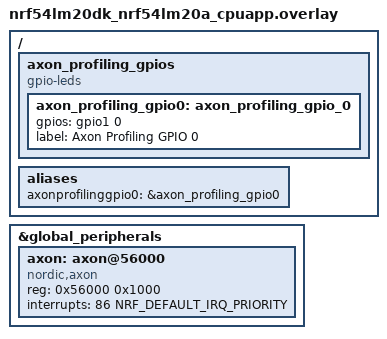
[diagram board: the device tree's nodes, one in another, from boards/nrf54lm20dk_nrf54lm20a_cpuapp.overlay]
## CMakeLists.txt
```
#
# Copyright (c) 2024, Nordic Semiconductor ASA. All Rights Reserved.
#
# The information contained herein is confidential property of Nordic Semiconductor ASA.
# The use, copying, transfer or disclosure of such information is prohibited except by
# express written agreement with Nordic Semiconductor ASA.
#
cmake_minimum_required(VERSION 3.20.0)

set(CMAKE_COMPILE_WARNING_AS_ERROR ON)

find_package(Zephyr REQUIRED HINTS $ENV{ZEPHYR_BASE})

project(axon_fe_mfcc VERSION 0.1.0 LANGUAGES C)

target_sources(app PRIVATE
	src/axon_app_mfcc_zephyr.c
	src/axon_app_mfcc.c
)

# 
# mfcc name is specified through kConfig. However for automated builds the
# environment variable AXON_MFCC_NAME can override kConfig.
#
if (DEFINED ENV{NRF_AXON_MFCC_NAME})
    message(STATUS "NRF_AXON_MFCC_NAME DEFINED $ENV{NRF_AXON_MFCC_NAME}, OVERRIDES CONFIG_NRF_AXON_MFCC_NAME ${CONFIG_NRF_AXON_MFCC_NAME}")
    zephyr_compile_definitions(
        NRF_AXON_MFCC_NAME=$ENV{NRF_AXON_MFCC_NAME}
    )
else()
    message(STATUS "NRF_AXON_MFCC_NAME NOT DEFINED, USING CONFIG_NRF_AXON_MFCC_NAME ${CONFIG_NRF_AXON_MFCC_NAME}")
    zephyr_compile_definitions(
        NRF_AXON_MFCC_NAME=${CONFIG_NRF_AXON_MFCC_NAME}
    )
endif()
```

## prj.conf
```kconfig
CONFIG_PRINTK=y
CONFIG_LOG=y
CONFIG_LOG_MODE_IMMEDIATE=y

CONFIG_NRF_AXON=y

CONFIG_NRF_AXON_MFCC=y
CONFIG_NRF_AXON_MFCC_NAME="16kfps_30ms_20ms_hann_fftmag_40fb_20to4khz_10coef"

CONFIG_OUTPUT_DISASSEMBLY=y
CONFIG_OUTPUT_DISASSEMBLE_ALL=y

CONFIG_MAIN_STACK_SIZE=4096

CONFIG_DEBUG_OPTIMIZATIONS=n
```

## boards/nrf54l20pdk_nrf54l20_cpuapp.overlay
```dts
/*
 * Copyright (c) 2023 Nordic Semiconductor ASA
 *
 * SPDX-License-Identifier: Apache-2.0
 */

// Include Axons
&global_peripherals {
	axons: axons@56000 {
		compatible = "nordic,axons";
		reg = <0x56000 0x1000>;
		interrupts = <86 NRF_DEFAULT_IRQ_PRIORITY>;
		status = "okay";
	};
};
```

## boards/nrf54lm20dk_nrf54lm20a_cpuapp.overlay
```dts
/*
 * Copyright (c) 2023 Nordic Semiconductor ASA
 *
 * SPDX-License-Identifier: Apache-2.0
 */

/ {

	// specify axon profiling gpio
	axon_profiling_gpios {
		compatible = "gpio-leds"; // profiling gpio acts just like an led.
		axon_profiling_gpio0: axon_profiling_gpio_0 {
			gpios = <&gpio1 0 GPIO_ACTIVE_HIGH>;
			label = "Axon Profiling GPIO 0";
		};
	};
	aliases {
		axonprofilinggpio0 = &axon_profiling_gpio0;
	};
};

// Include Axons
&global_peripherals {
	axon: axon@56000 {
		compatible = "nordic,axon";
		reg = <0x56000 0x1000>;
		interrupts = <86 NRF_DEFAULT_IRQ_PRIORITY>;
		status = "okay";
	};
};
```

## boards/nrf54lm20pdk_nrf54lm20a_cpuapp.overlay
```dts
/*
 * Copyright (c) 2023 Nordic Semiconductor ASA
 *
 * SPDX-License-Identifier: Apache-2.0
 */

/ {

	// specify axon profiling gpio
	axon_profiling_gpios {
		compatible = "gpio-leds"; // profiling gpio acts just like an led.
		axon_profiling_gpio0: axon_profiling_gpio_0 {
			gpios = <&gpio1 0 GPIO_ACTIVE_HIGH>;
			label = "Axon Profiling GPIO 0";
		};
	};
	aliases {
		axonprofilinggpio0 = &axon_profiling_gpio0;
	};
};

// Include Axons
&global_peripherals {
	axons: axons@56000 {
		compatible = "nordic,axons";
		reg = <0x56000 0x1000>;
		interrupts = <86 NRF_DEFAULT_IRQ_PRIORITY>;
		status = "okay";
	};
};
```

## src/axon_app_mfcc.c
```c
/*
 * Copyright (c) 2024, Nordic Semiconductor ASA. All Rights Reserved.
 *
 * The information contained herein is confidential property of Nordic Semiconductor ASA.
 * The use, copying, transfer or disclosure of such information is prohibited except by
 * express written agreement with Nordic Semiconductor ASA.
 */

#include <stdio.h>
#include <stdlib.h>
#include <string.h>
#include "drivers/axon/nrf_axon_driver.h"
#include "axon/nrf_axon_platform.h"
#include "axon/mfcc/axon_mfcc.h"
#include "axon/nrf_axon_logging.h"
#if (NOT_A_ZEPHYR_BUILD)
#include "axon/nrf_axon_platform_simulator.h"
#endif

/*
 * AUDIO TEST VECTORS
 */
#include "test_audio/rawSampleon.h"

static const struct {
  const char *sample_label;
  int32_t sample_count;
  const int16_t *wave_data;
  const int8_t *pexpected_output_quantizedected_output;
  const int32_t *expected_output_unquantized;
  const int8_t *expected_output_quantized;
}  audio_sample_files[] ={
  {
      .sample_label = AUDIO_NAME_ON,
      .sample_count = sizeof(wave_data_on)/sizeof(wave_data_on[0]),
      .wave_data = wave_data_on,
      .expected_output_unquantized = (const int32_t *)PPCAT3(expected_unquantized_mfcc_output_on, _, NRF_AXON_MFCC_NAME),
      .expected_output_quantized = (const int8_t *)PPCAT3(expected_quantized_mfcc_output_on, _, NRF_AXON_MFCC_NAME),
  }
};

/**
 * use macro chicanery to generate symbol names assocatiated with the mfcc target name.
 */
const int32_t quant_inverse_scaling_factor =  PPCAT3(MFCC_QUANT_INV_SCALE_FACTOR, _, NRF_AXON_MFCC_NAME);
const int8_t quant_inverse_scaling_factor_radix =  PPCAT3(MFCC_QUANT_INV_SCALE_FACTOR_RADIX, _, NRF_AXON_MFCC_NAME);
const int8_t quant_zero_point =  PPCAT3(MFCC_QUANT_ZERO_POINT, _, NRF_AXON_MFCC_NAME);

static struct {
  char test_name[50];
  uint32_t case_no;
  uint32_t case_count_total;
  uint32_t case_count_pass;
} axon_test_info = {0};

/*
 * Processes a single audio vector, and optionally compares the results to the passed expected_output.
 * 
 */
int axon_mfcc_process_vector(const int16_t *audio_vector, 
              uint32_t audio_vector_len, 
              uint8_t input_stride, 
              const AXON_MFCC_DATA_TYPE* expected_output,
              AXON_MFCC_DATA_TYPE* output_vector,
              int32_t* output_vector_unquantized) {
  
  nrf_axon_result_e result = NRF_AXON_RESULT_SUCCESS;
  uint32_t frame_idx;
  AXON_MFCC_DATA_TYPE output[AXON_MFCC_WIDTH];
  axon_mfcc_restart();

  /*
   * loop through the vector, one frame at a time.
   */
  for (frame_idx=0;
      frame_idx<=((audio_vector_len-AXON_MFCC_FRAME_LEN)/AXON_MFCC_FRAME_SHIFT);
      frame_idx++,audio_vector += AXON_MFCC_FRAME_SHIFT*input_stride) {

    if(NULL != expected_output) {
      nrf_axon_platform_printf("\n\rTEST:\t%s\tSTART CASE NO\t%d\n", axon_test_info.test_name, axon_test_info.case_no);
    }
    result=axon_mfcc_process_frame(audio_vector, AXON_MFCC_FRAME_LEN, NULL, false, input_stride, output);
    if (result < 0) {
      nrf_axon_platform_printf("axon_mfcc_process_frame error %d\n", result);
      // error!
      break;
    }
    if (result < 0) {
      // error!
      break;
    }
    // save the output to the output vector
    if (NULL != output_vector) {
      memcpy(output_vector+AXON_MFCC_WIDTH*frame_idx, output, sizeof(AXON_MFCC_DATA_TYPE)*AXON_MFCC_WIDTH);
    }
    // same for unquantized output
    if (NULL != output_vector_unquantized) {
      axon_mfcc_get_unquantized_outputs(output_vector_unquantized+AXON_MFCC_WIDTH*frame_idx);
    }

    // compare to exected value
    if (NULL != expected_output) {
      if (sizeof(AXON_MFCC_DATA_TYPE)==1) {
        char name[20];
        snprintf(name, sizeof(name), "frame_%02d", frame_idx);
        nrf_axon_print_int8_vector(name, output, AXON_MFCC_WIDTH);
        if(0 == nrf_axon_verify_vectors_8(name, output, expected_output+frame_idx*AXON_MFCC_WIDTH, AXON_MFCC_WIDTH, 1)){
          nrf_axon_platform_printf("\n\rTEST:\t%s\tCASE NO\t%d\tRESULT:\t%s\n", axon_test_info.test_name, axon_test_info.case_no, "PASS");
          axon_test_info.case_count_pass++;
        } else {
          nrf_axon_platform_printf("\n\rTEST:\t%s\tCASE NO\t%d\tRESULT:\t%s\n", axon_test_info.test_name, axon_test_info.case_no, "FAIL");
        }
        axon_test_info.case_no++;
        nrf_axon_platform_printf("mfcc calc time:%u\n", axon_mfcc_return_profiling_ticks());
      } else if (sizeof(AXON_MFCC_DATA_TYPE)==4) {
        char name[20];
        snprintf(name, sizeof(name), "frame_%02d", frame_idx);
        nrf_axon_print_int32_vector(name, (int32_t *)output, AXON_MFCC_WIDTH, 1);
        if(0 == nrf_axon_verify_vectors(name, (int32_t *)output, (int32_t *)expected_output+frame_idx*AXON_MFCC_WIDTH, AXON_MFCC_WIDTH, 1)){
          nrf_axon_platform_printf("\n\rTEST:\t%s\tCASE NO\t%d\tRESULT:\t%s\n", axon_test_info.test_name, axon_test_info.case_no, "PASS");
          axon_test_info.case_count_pass++;
        } else {
          nrf_axon_platform_printf("\n\rTEST:\t%s\tCASE NO\t%d\tRESULT:\t%s\n", axon_test_info.test_name, axon_test_info.case_no, "FAIL");
        }
        axon_test_info.case_no++;
        nrf_axon_platform_printf("mfcc calc time:%u\n", axon_mfcc_return_profiling_ticks());
      }
    }
  }

  return result;
}

/*
 *
 */
int axon_mfcc_app_init() {
  return axon_mfcc_calculate_init(
    quant_inverse_scaling_factor,
    quant_inverse_scaling_factor_radix,
    quant_zero_point
  );
}

int axon_mfcc_run_compiled_in_vectors(char* test_name_root) {
  uint32_t audio_sample_ndx;
  for(audio_sample_ndx=0;
      audio_sample_ndx < sizeof(audio_sample_files)/sizeof(audio_sample_files[0]);
      audio_sample_ndx++) {
    nrf_axon_platform_printf("\r\n\r\n");
    nrf_axon_platform_printf("Audio Name: %s\r\n", audio_sample_files[audio_sample_ndx].sample_label);

    strcpy(axon_test_info.test_name, test_name_root);
    strcat(axon_test_info.test_name, audio_sample_files[audio_sample_ndx].sample_label);
    axon_test_info.case_count_total = ((audio_sample_files[audio_sample_ndx].sample_count-AXON_MFCC_FRAME_LEN)/AXON_MFCC_FRAME_SHIFT)+1;
    axon_test_info.case_count_pass = 0;
    axon_test_info.case_no = 0;
    nrf_axon_platform_printf("\n\rTEST:\t%s\tCASE COUNT\t%d\n", axon_test_info.test_name, axon_test_info.case_count_total);
    
    axon_mfcc_process_vector(audio_sample_files[audio_sample_ndx].wave_data, // samples
        audio_sample_files[audio_sample_ndx].sample_count,  // # of samples
        1, // Stride between samples. For mono this is 1, for stereo it's 2
#if AXON_MFCC_QUANT_ENABLE        
        audio_sample_files[audio_sample_ndx].expected_output_quantized,
#else
        audio_sample_files[audio_sample_ndx].expected_output_unquantized,
#endif
        NULL, // don't want the output vector
        NULL  // nor do we want the unquantized output vector
        );   // expected output to compare to (can be null)

    nrf_axon_platform_printf("\n\rTEST:\t%s\tCOMPLETE\tPASS COUNT\t%d\tFAIL COUNT\t%d\n", axon_test_info.test_name, axon_test_info.case_count_pass, axon_test_info.case_count_total-axon_test_info.case_count_pass);
  }

  return 0;
}

/**
 * top level function for testing compiled in vectors.
 * Runs on simulator and in Zephyr
 */
int main_mfcc_test_compiled_in_vectors()
{
  nrf_axon_platform_printf("\n\n\rStart axon_app_mfcc!\n\r");

  nrf_axon_result_e result = nrf_axon_platform_init();

  if (result != NRF_AXON_RESULT_SUCCESS) {
    nrf_axon_platform_printf("\n\axon_platform_init failed!\n");
    return result;
  }

  axon_mfcc_app_init();

  // iterate through the compiled-in test vectors
  axon_mfcc_run_compiled_in_vectors("axon_fe_mfcc_");

  nrf_axon_platform_printf("\r\n axon_app_mfcc complete!\r\n");
  nrf_axon_platform_close();

  return 0;
}
```

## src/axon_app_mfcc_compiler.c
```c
/*
 * Copyright (c) 2024, Nordic Semiconductor ASA. All Rights Reserved.
 *
 * The information contained herein is confidential property of Nordic Semiconductor ASA.
 * The use, copying, transfer or disclosure of such information is prohibited except by
 * express written agreement with Nordic Semiconductor ASA.
 */

#include <stddef.h>
#include <stdio.h>
#include <string.h>
#include "drivers/axon/nrf_axon_driver.h"
#include "axon/mfcc/axon_mfcc.h"
#include "axon/nrf_axon_platform.h"
#if (NOT_A_ZEPHYR_BUILD)
#include "axon/nrf_axon_platform_simulator.h"
#endif

static FILE* compiler_output_file = NULL;

extern int axon_mfcc_app_init();
extern int axon_mfcc_run_compiled_in_vectors(char*);
void axon_compiler_set_intrinsic_compiler_file(FILE*);

int main()
{
  nrf_axon_platform_printf("\n\n\rStart axon_app_mfcc_compiler!\r\n");

  // open the compiled command buffer file.
  // note that this flie name has a relative path in it for when reading the file. Need to strip that off before writing it.
  const char *name_only = AXON_MFCC_CMD_BUF_FILE_NAME;
  unsigned name_len = strlen(name_only);
  name_only += name_len;
  for(unsigned ndx=0; ndx < name_len; ndx++,name_only--) {
    if (*name_only == '/') {
      name_only++;
      break;
    }
  }
  if (0 != fopen_s(&compiler_output_file, name_only, "w+")) {
    printf("ERROR: unable to create file: %s\n", name_only);
    return -3;
  }

  // pass this file to the compiler
  axon_compiler_set_intrinsic_compiler_file(compiler_output_file);

  extern bool simulator_in_threadless_mode;
  simulator_in_threadless_mode = true;
  nrf_axon_result_e result = nrf_axon_platform_init();

  if (result != NRF_AXON_RESULT_SUCCESS) {
    nrf_axon_platform_printf("\nInitInstance failed!\n");
  }

  axon_mfcc_app_init();

  // iterate through the compiled-in 
  axon_mfcc_run_compiled_in_vectors("axon_fe_mfcc_compiler_");

  /**
   * @FIXME!!! NEED TO READ-IN TEST VECTORS FROM FILE!!
  */
  fclose(compiler_output_file);

  nrf_axon_platform_printf("\r\n axon_app_mfcc_compiler complete!\r\n");
  nrf_axon_platform_close();

  
  return 0;
}
```

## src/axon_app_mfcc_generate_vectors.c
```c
/*
 * Copyright (c) 2024, Nordic Semiconductor ASA. All Rights Reserved.
 *
 * The information contained herein is confidential property of Nordic Semiconductor ASA.
 * The use, copying, transfer or disclosure of such information is prohibited except by
 * express written agreement with Nordic Semiconductor ASA.
 */

/**
 * Top level file for generating test vectors.
 * For simulator builds only.
 * Reads in a series of raw audio vectors from an csv files, and writes the corresponding mfccs to an output csv file.
 */

#include <stddef.h>
#include <stdio.h>
#include <string.h>
#include "drivers/axon/nrf_axon_driver.h"
#include "axon/nrf_axon_platform.h"
#include "axon/mfcc/axon_mfcc.h"
#if (NOT_A_ZEPHYR_BUILD)
#include "axon/nrf_axon_platform_simulator.h"
#endif

const int32_t quant_inverse_scaling_factor = 1;
const int8_t quant_inverse_scaling_factor_radix = 0;
const int8_t quant_zero_point = 0;

static int write_results_to_file(FILE* output_file, int32_t *mfccs, uint32_t mfcc_slice_cnt) {
  uint32_t i;
  for (i=0; i<AXON_MFCC_WIDTH*mfcc_slice_cnt-1; i++) {
    fprintf(output_file, "%d,", *(mfccs+i));
  }
  fprintf(output_file, "%d\n", *(mfccs+i));

  return 0;
}

/*
 * Processes a single audio vector, and optionally compares the results to the passed expected_output.
 * 
 */
static int axon_mfcc_process_input_vector(const int16_t *audio_vector, 
              uint32_t audio_vector_len, 
              uint8_t input_stride, 
              AXON_MFCC_DATA_TYPE* output_vector,
              int32_t* output_vector_unquantized) {
  
  nrf_axon_result_e result = NRF_AXON_RESULT_SUCCESS;
  uint32_t frame_idx;
  AXON_MFCC_DATA_TYPE output[AXON_MFCC_WIDTH];
  axon_mfcc_restart();

  /*
   * loop through the vector, one frame at a time.
   */
  for (frame_idx=0;
      frame_idx<=((audio_vector_len-AXON_MFCC_FRAME_LEN)/AXON_MFCC_FRAME_SHIFT);
      frame_idx++,audio_vector += AXON_MFCC_FRAME_SHIFT*input_stride) {

    result=axon_mfcc_process_frame(audio_vector, AXON_MFCC_FRAME_LEN, NULL, false, input_stride, output);
    if (result < 0) {
      nrf_axon_platform_printf("axon_mfcc_process_frame error %d\n", result);
      // error!
      break;
    }
    if (result < 0) {
      // error!
      break;
    }
    // save the output to the output vector
    if (NULL != output_vector) {
      memcpy(output_vector+AXON_MFCC_WIDTH*frame_idx, output, sizeof(AXON_MFCC_DATA_TYPE)*AXON_MFCC_WIDTH);
    }
    // same for unquantized output
    if (NULL != output_vector_unquantized) {
      axon_mfcc_get_unquantized_outputs(output_vector_unquantized+AXON_MFCC_WIDTH*frame_idx);
    }
  }

  return result;
}

static int process_mfcc_input_file(char* input_file_name, char* output_file_name, int8_t* buffer, uint32_t buffer_size) {
  FILE* input_vectors_file = NULL;
  FILE* output_vectors_file = NULL;
  int16_t *input_audio_vector = (int16_t *)buffer;
  uint32_t input_buffer_length = buffer_size/sizeof(*input_audio_vector);
  uint32_t input_vector_length;
  #define MFCC_BUFFER_LENGTH (AXON_MFCC_SLICE_CNT * AXON_MFCC_WIDTH * 2)
  static int32_t unquantized_mfccs[MFCC_BUFFER_LENGTH];
  

  if (0 != fopen_s(&input_vectors_file, input_file_name, "r")) {
    nrf_axon_platform_printf("ERROR: unable to read file: %s\n", input_file_name);
    return -2;
  }

  if (0 != fopen_s(&output_vectors_file, output_file_name, "w")) {
    nrf_axon_platform_printf("ERROR: unable to create file: %s\n", output_file_name);
    return -3;
  }

  while (!feof(input_vectors_file)) {
    input_vector_length = read_in_test_vector_int16(input_vectors_file, input_audio_vector, input_buffer_length);
    if (0 >= input_vector_length) {
      break;
    }

  unsigned slices_in_audio_vector = ((input_vector_length-AXON_MFCC_FRAME_LEN)/AXON_MFCC_FRAME_SHIFT)+1;
  // Only process the ones we can handle in the mfcc buffer
  if (slices_in_audio_vector > (AXON_MFCC_SLICE_CNT*2)) {
    slices_in_audio_vector = (AXON_MFCC_SLICE_CNT*2);
  }

  axon_mfcc_process_input_vector(input_audio_vector, // samples
        input_vector_length,  // # of samples
        1, // Stride between samples. For mono this is 1, for stereo it's 2
        NULL, // don't wan't quantized results
        unquantized_mfccs // get the quantized mfccs
        );   // expected output to compare to (can be null)

    write_results_to_file(output_vectors_file, unquantized_mfccs, slices_in_audio_vector);
  }

  fclose(input_vectors_file);
  fclose(output_vectors_file);

  return 0;
}

static int mfcc_generate_vectors(char* input_path, char* output_path)
{
  /**
  * Size the input buffer to 2x the expected size needed. This is the number of samples * size_of_each_sample_as_text
  * Each audio sample is 16bits which is a maximum of 6characters (including minus sign) + 1 for each comma.
  */
#define INPUT_BUFFER_SIZE ((AXON_MFCC_SLICE_CNT * AXON_MFCC_FRAME_SHIFT + AXON_MFCC_FRAME_LEN) * 7 * 2)

  nrf_axon_platform_printf("\n\n\rStart axon_app_mfcc_generate_vectors!\n\r");

  extern bool simulator_in_threadless_mode;
  simulator_in_threadless_mode = true;
  nrf_axon_result_e result = nrf_axon_platform_init();

  if (result != NRF_AXON_RESULT_SUCCESS) {
    nrf_axon_platform_printf("\n\axon_platform_init failed!\n");
    return result;
  }

  axon_mfcc_calculate_init(
    quant_inverse_scaling_factor,
    quant_inverse_scaling_factor_radix,
    quant_zero_point
  );

  nrf_axon_platform_printf("\n\nAxon MFCC get input files (*.csv) from folder %s ...\n", input_path);
  if(0 == nrf_axon_simulator_run_test_files(input_path, output_path, ".csv", "mfcc_", INPUT_BUFFER_SIZE, process_mfcc_input_file)) {
    nrf_axon_platform_printf("Axon MFCC output result files to folder %s\n", output_path);
  }

  nrf_axon_platform_printf("\r\n axon_app_mfcc complete!\r\n");
  nrf_axon_platform_close();

  
  return 0;
}


int main(int argc, char *argv[]) {
  char *mfcc_in=NULL;
  char *mfcc_out=NULL;
    if(argc >= 3) {
      mfcc_in = argv[1];
      mfcc_out = argv[2];
    } else {
      nrf_axon_platform_printf("\r\n Warning: paths for input files and output files not provided! Cmd format: exe <input_folder> <output_folder>\nUsing ../../mfcc_in ../../mfcc_out\n");
      mfcc_in = "../../mfcc_in";
      mfcc_out = "../../mfcc_out";

      /*
      nrf_axon_platform_printf("\r\n Error: please give pathes for input files and output files respectively! Cmd format: exe <input_folder> <output_folder>\n\n");
      return -1;
      */
    }
  return mfcc_generate_vectors(mfcc_in, mfcc_out);
}
```

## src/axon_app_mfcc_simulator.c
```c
/*
 * Copyright (c) 2024, Nordic Semiconductor ASA. All Rights Reserved.
 *
 * The information contained herein is confidential property of Nordic Semiconductor ASA.
 * The use, copying, transfer or disclosure of such information is prohibited except by
 * express written agreement with Nordic Semiconductor ASA.
 */
/**
 * top level file for axon_app_mfcc for simultor builds to run compiled-in vectors.
 */
#include <stddef.h>
#include <stdio.h>
#include "drivers/axon/nrf_axon_driver.h"
#include "axon/nrf_axon_platform.h"

extern int main_mfcc_test_compiled_in_vectors();

int main(int argc, char *argv[]) {
    // Start inference
  return main_mfcc_test_compiled_in_vectors();
}
```

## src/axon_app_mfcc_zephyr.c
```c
/*
 * Copyright (c) 2022 Nordic Semiconductor ASA
 *
 * SPDX-License-Identifier: LicenseRef-Nordic-5-Clause
 */

/**
 * top level file for axon_app_mfcc for zephyr builds.
 * Runs compiled-in vectors.
 */

#include <zephyr/kernel.h>
#include <zephyr/irq.h>
#include <zephyr/sys_clock.h>
#include <zephyr/sys/printk.h>

#include <zephyr/logging/log.h>

// #define MY_LOG_LEVEL LOG_LEVEL_NONE
#define MY_LOG_LEVEL LOG_LEVEL_DBG

LOG_MODULE_REGISTER(kws, MY_LOG_LEVEL);

extern int main_mfcc_test_compiled_in_vectors();
int main(void)
{
  while (1) {
    printk("axon_fe_mfcc on %s\n", CONFIG_BOARD);

    // Start inference
    main_mfcc_test_compiled_in_vectors();

    k_sleep(K_FOREVER);
  }
  return 0;
}
```

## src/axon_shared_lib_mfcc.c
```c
/*
 * Copyright (c) 2024, Nordic Semiconductor ASA. All Rights Reserved.
 *
 * The information contained herein is confidential property of Nordic Semiconductor ASA.
 * The use, copying, transfer or disclosure of such information is prohibited except by
 * express written agreement with Nordic Semiconductor ASA.
 */

#include <stddef.h>
#include <stdio.h>
#include "drivers/axon/nrf_axon_driver.h"
#include "axon/nrf_axon_platform.h"
#include "axon/mfcc/axon_mfcc.h"

extern int axon_mfcc_app_init();

EXPORT_API int axon_mfcc_lib_calc_mfcc(const int16_t *audio_in, unsigned audio_in_len, int32_t *mfccs_out, unsigned mfccs_out_len, unsigned *mfccs_out_width){
  static bool inited = false;
  if (!inited) {
    // parameter checking and initialization only occurs on 1st call.
    if (NULL==audio_in) {
      nrf_axon_platform_printf("ERROR! calc_mfcc audio_in is NULL\n");
      return -1;
    }
    if (NULL==mfccs_out) {
      nrf_axon_platform_printf("ERROR! calc_mfcc mfccs_out is NULL\n");
      return -2;
    }
    if (NULL==mfccs_out_width) {
      nrf_axon_platform_printf("ERROR! calc_mfcc out_width is NULL\n");
      return -3;
    }
    if (4 != sizeof(AXON_MFCC_DATA_TYPE)) {
      nrf_axon_platform_printf("ERROR! calc_mfcc mfccs compiled with quantization enabled\n");
      return -4;
    }
    nrf_axon_platform_printf("\nStart axons_shared_lib_mfcc!\n");

    nrf_axon_result_e result = nrf_axon_platform_init();

    if (result != NRF_AXON_RESULT_SUCCESS) {
      nrf_axon_platform_printf("\n\axon_platform_init failed!\n");
      return result;
    }
    axon_mfcc_app_init();
    inited = true;
  }
  *mfccs_out_width = AXON_MFCC_WIDTH;
  int slice_cnt = 0; 
  int32_t unused_output[AXON_MFCC_WIDTH]; // buffer to hold out that might be quantized.
  
  //loop until reach end of audio_in or mfccs_Out
  while ( (audio_in_len >= AXON_MFCC_FRAME_LEN) && 
           (mfccs_out_len >= AXON_MFCC_WIDTH)) {
    nrf_axon_result_e result=axon_mfcc_process_frame(audio_in, AXON_MFCC_FRAME_LEN, NULL, false, 1, unused_output);

    if (result < 0) {
      nrf_axon_platform_printf("ERROR! calc_mfccs failure %d on slice %d\n", result, slice_cnt);
      return result;
    }
    // now get the unquantized output
    axon_mfcc_get_unquantized_outputs(mfccs_out);

    // decrement counts...
    audio_in_len -= AXON_MFCC_FRAME_SHIFT;
    mfccs_out_len -= AXON_MFCC_WIDTH;
    // ...advance pointers
    audio_in += AXON_MFCC_FRAME_SHIFT;
    mfccs_out += AXON_MFCC_WIDTH;
    slice_cnt++;
  }
  return slice_cnt;

}

EXPORT_API void axon_mfcc_lib_close(){
  /**
   * @FIXME!!! PRINT OVERFLOW TOTALS HERE!
   */
  nrf_axon_platform_close();
}
```
